# STM32H7A3 register map
File version: 2.6
CPU: CM7 r0p1, little endian, MPU, FPU, 4 interrupt priority bits
Registers are 32-bit, read-write, reset 0x0 unless marked. A register's access mark holds for its fields unless they carry their own. Offsets are from the block's base; [hi:lo] are bit positions; {n}, {i} and the like mark numbered series; 'fields as' and 'values as' point back to an identical list.

## HRTIM_Master — High Resolution Timer: Master Timers
Base 0x40017400
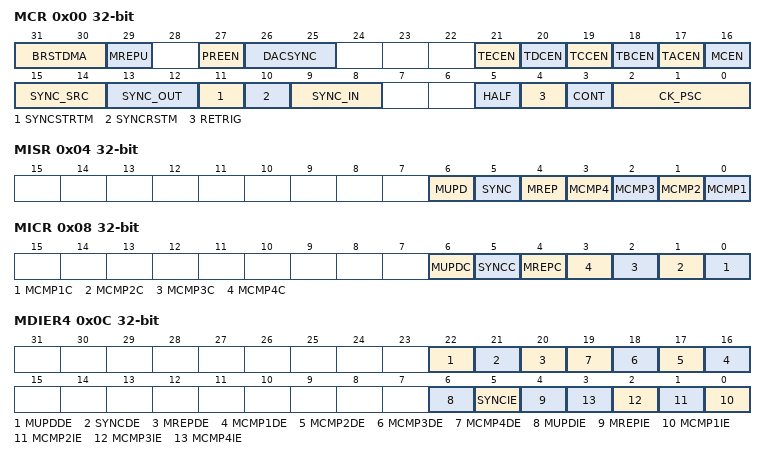
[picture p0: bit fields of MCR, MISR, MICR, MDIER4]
0x00 MCR — Master Timer Control Register
  [31:30] BRSTDMA — Burst DMA Update
  [29] MREPU — Master Timer Repetition update
  [27] PREEN — Preload enable
  [26:25] DACSYNC — AC Synchronization
  [21] TECEN — Timer E counter enable
  [20] TDCEN — Timer D counter enable
  [19] TCCEN — Timer C counter enable
  [18] TBCEN — Timer B counter enable
  [17] TACEN — Timer A counter enable
  [16] MCEN — Master Counter enable
  [15:14] SYNC_SRC — Synchronization source
  [13:12] SYNC_OUT — Synchronization output
  [11] SYNCSTRTM — Synchronization Starts Master
  [10] SYNCRSTM — Synchronization Resets Master
  [9:8] SYNC_IN — ynchronization input
  [5] HALF — Half mode enable
  [4] RETRIG — Master Re-triggerable mode
  [3] CONT — Master Continuous mode
  [2:0] CK_PSC — HRTIM Master Clock prescaler
0x04 MISR ro — Master Timer Interrupt Status Register
  [6] MUPD — Master Update Interrupt Flag
  [5] SYNC — Sync Input Interrupt Flag
  [4] MREP — Master Repetition Interrupt Flag
  [n-1] MCMP{n} (n=1..4) — Master Compare {n} Interrupt Flag
0x08 MICR wo — Master Timer Interrupt Clear Register
  [6] MUPDC — Master update Interrupt flag clear
  [5] SYNCC — Sync Input Interrupt flag clear
  [4] MREPC — Repetition Interrupt flag clear
  [n-1] MCMP{n}C (n=1..4) — Master Compare {n} Interrupt flag clear
0x0C MDIER4
  [22] MUPDDE, [21] SYNCDE, [20] MREPDE, [n+15] MCMP{n}DE (n=1..4), [6] MUPDIE, [5] SYNCIE, [4] MREPIE, [n-1] MCMP{n}IE (n=1..4)
0x10 MCNTR — Master Timer Counter Register
  [15:0] MCNT — Counter value
0x14 MPER reset 0xFFFF — Master Timer Period Register
  [15:0] MPER — Master Timer Period value
0x18 MREP — Master Timer Repetition Register
  [7:0] MREP — Master Timer Repetition counter value
0x1C MCMP1R — Master Timer Compare 1 Register
  [15:0] MCMP1 — Master Timer Compare 1 value
{0x1C+4i} MCMP{i}R (i=2..4) — Master Timer Compare {i} Register
  [15:0] MCMP{i} — Master Timer Compare {i} value

## HSEM
Base 0x48020800
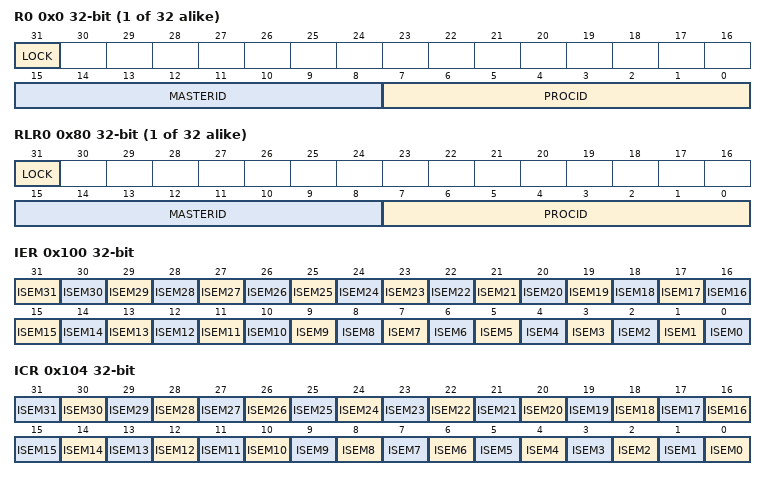
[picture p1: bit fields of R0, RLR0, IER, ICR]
{0x0+4i} R{i} (i=0..31) — HSEM register HSEM_R0 HSEM_R31
  [31] LOCK — Lock indication
  [15:8] MASTERID — Semaphore MasterID
  [7:0] PROCID — Semaphore ProcessID
{0x80+4i} RLR{i} ro (i=0..31) — HSEM Read lock register
  fields as R0
0x100 IER — HSEM Interrupt enable register
  [31] ISEM31 — Interrupt(N) semaphore n enable bit.
  [n] ISEM{n} (n=0..30) — Interrupt semaphore n enable bit
0x104 ICR ro — HSEM Interrupt clear register
  [n] ISEM{n} (n=0..31) — Interrupt(N) semaphore n clear bit
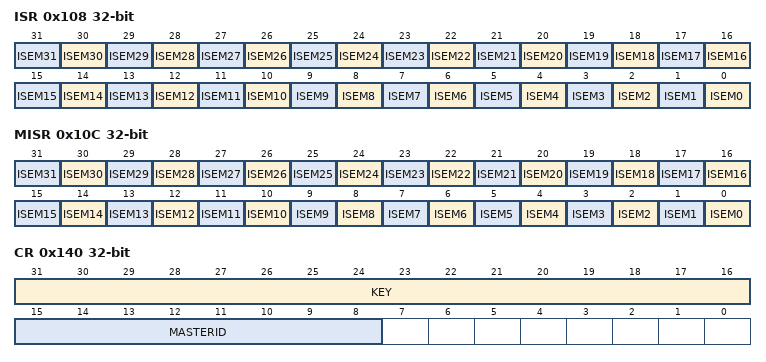
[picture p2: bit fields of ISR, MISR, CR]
0x108 ISR ro — HSEM Interrupt status register
  [n] ISEM{n} (n=0..31) — Interrupt(N) semaphore n status bit before enable (mask)
0x10C MISR ro — HSEM Masked interrupt status register
  [n] ISEM{n} (n=0..31) — masked interrupt(N) semaphore n status bit after enable (mask)
0x140 CR — HSEM Clear register
  [31:16] KEY — Semaphore clear Key
  [15:8] MASTERID — MasterID of semaphores to be cleared
0x144 KEYR — HSEM Interrupt clear register
  [31:16] KEY — Semaphore Clear Key

## LPTIM1 — Low power timer
Base 0x40002400
Same registers: LPTIM2 0x58002400
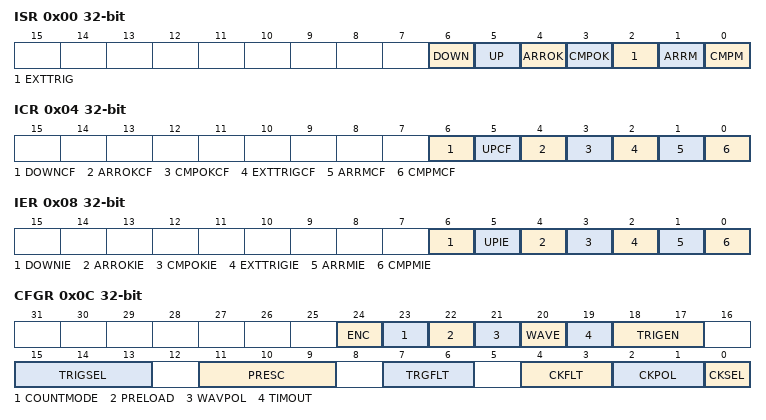
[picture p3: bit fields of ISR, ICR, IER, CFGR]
0x00 ISR ro — Interrupt and Status Register
  [6] DOWN — Counter direction change up to down
  [5] UP — Counter direction change down to up
  [4] ARROK — Autoreload register update OK
  [3] CMPOK — Compare register update OK
  [2] EXTTRIG — External trigger edge event
  [1] ARRM — Autoreload match
  [0] CMPM — Compare match
0x04 ICR wo — Interrupt Clear Register
  [6] DOWNCF — Direction change to down Clear Flag
  [5] UPCF — Direction change to UP Clear Flag
  [4] ARROKCF — Autoreload register update OK Clear Flag
  [3] CMPOKCF — Compare register update OK Clear Flag
  [2] EXTTRIGCF — External trigger valid edge Clear Flag
  [1] ARRMCF — Autoreload match Clear Flag
  [0] CMPMCF — compare match Clear Flag
0x08 IER — Interrupt Enable Register
  [6] DOWNIE — Direction change to down Interrupt Enable
  [5] UPIE — Direction change to UP Interrupt Enable
  [4] ARROKIE — Autoreload register update OK Interrupt Enable
  [3] CMPOKIE — Compare register update OK Interrupt Enable
  [2] EXTTRIGIE — External trigger valid edge Interrupt Enable
  [1] ARRMIE — Autoreload match Interrupt Enable
  [0] CMPMIE — Compare match Interrupt Enable
0x0C CFGR — Configuration Register
  [24] ENC — Encoder mode enable
  [23] COUNTMODE — counter mode enabled
  [22] PRELOAD — Registers update mode
  [21] WAVPOL — Waveform shape polarity
  [20] WAVE — Waveform shape
  [19] TIMOUT — Timeout enable
  [18:17] TRIGEN — Trigger enable and polarity
  [15:13] TRIGSEL — Trigger selector
  [11:9] PRESC — Clock prescaler
  [7:6] TRGFLT — Configurable digital filter for trigger
  [4:3] CKFLT — Configurable digital filter for external clock
  [2:1] CKPOL — Clock Polarity
  [0] CKSEL — Clock selector
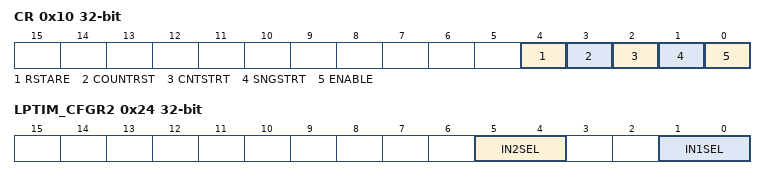
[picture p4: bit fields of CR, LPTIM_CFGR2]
0x10 CR — Control Register
  [4] RSTARE — Reset after read enable
  [3] COUNTRST — Counter reset
  [2] CNTSTRT — Timer start in continuous mode
  [1] SNGSTRT — LPTIM start in single mode
  [0] ENABLE — LPTIM Enable
0x14 CMP — Compare Register
  [15:0] CMP — Compare value
0x18 ARR reset 0x1 — Autoreload Register
  [15:0] ARR — Auto reload value
0x1C CNT ro — Counter Register
  [15:0] CNT — Counter value
0x24 LPTIM_CFGR2 — LPTIM configuration register 2
  [5:4] IN2SEL — LPTIM Input 2 selection
  [1:0] IN1SEL — LPTIM Input 1 selection

## LPTIM3 — Low power timer
Base 0x58002800
Registers as LPTIM1; these are added or differ:
0x24 LPTIM_CFGR2 — LPTIM configuration register 2
  [1:0] IN1SEL — LPTIM Input 1 selection

## Notices in the file
Copyright (c) 2023 STMicroelectronics.
SPDX-License-Identifier: Apache-2.0
Licensed under the Apache License, Version 2.0 (the "License");
you may not use this file except in compliance with the License.
You may obtain a copy of the License at
http://www.apache.org/licenses/LICENSE-2.0
Unless required by applicable law or agreed to in writing, software
distributed under the License is distributed on an "AS IS" BASIS,
WITHOUT WARRANTIES OR CONDITIONS OF ANY KIND, either express or implied.
See the License for the specific language governing permissions and
limitations under the License.
